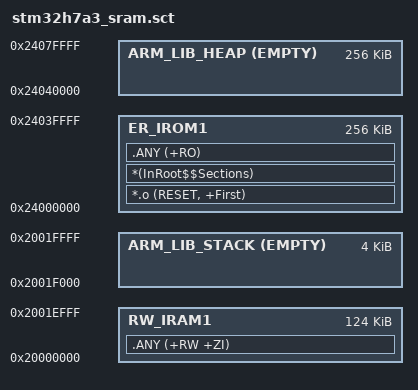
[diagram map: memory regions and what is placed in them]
;*******************************************************************
;* STM32H7A3 linker scatter file (running code from internal SRAM) *
;*******************************************************************

LR_IROM1 0x24000000 0x40000
{
   ER_IROM1 0x24000000 0x40000
   {
      *.o (RESET, +First)
      *(InRoot$$Sections)
      .ANY (+RO)
   }
   
   RW_IRAM1 0x20000000 0x1F000
   { 
      .ANY (+RW +ZI)
   }
   
   ARM_LIB_STACK 0x20020000 EMPTY -0x1000
   {
   }
   
   ARM_LIB_HEAP 0x24040000 EMPTY 0x40000
   {
   }
}
